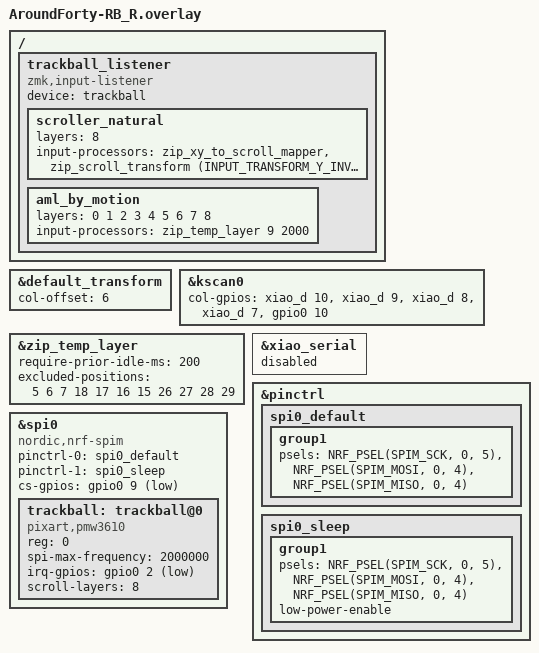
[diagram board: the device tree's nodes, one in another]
/* AroundForty-RB_R.overlay（Input Processor: AML + スクロールY反転 + excluded-positions + 2秒タイムアウト） */

#include "AroundForty-RB.dtsi"

/* Input Processor 利用 */
#include <input/processors.dtsi>
#include <dt-bindings/zmk/input_transform.h>

&default_transform {
    col-offset = <6>;
};

&kscan0 {
        col-gpios
            = <&xiao_d 10 GPIO_ACTIVE_HIGH>
            , <&xiao_d 9 GPIO_ACTIVE_HIGH>
            , <&xiao_d 8 GPIO_ACTIVE_HIGH>
            , <&xiao_d 7 GPIO_ACTIVE_HIGH>
            , <&gpio0 10 GPIO_ACTIVE_HIGH>
            ;
};

/* ▼ AML の“解除ルール”と“誤爆防止” */
&zip_temp_layer {
    /* 直前200ms以内にキー入力があれば AML を起動しない（誤爆防止） */
    require-prior-idle-ms = <200>;

    /* マウスキーの position → 押しても解除しない（指定以外は押したら即解除） */
    excluded-positions = <
        5 6 7
        18 17 16 15
        26 27 28 29
    >;
};

&xiao_serial { status = "disabled"; };

 /{
    /* トラックボール・リスナー */
    trackball_listener {
        compatible = "zmk,input-listener";
        device = <&trackball>;

        /* スクロール用レイヤのみで“縦スクロール反転”（ナチュラル想定） */
        scroller_natural {
            layers = <8>; /* ← Scloll_Layer のレイヤ番号に合わせる */
            input-processors =
                <&zip_xy_to_scroll_mapper>,
                <&zip_scroll_transform (INPUT_TRANSFORM_Y_INVERT)>;
        };

        /* AML：トラックボールを動かしたら MOUSE レイヤを 2秒だけ自動ON
           ※ layers が必須なので、デフォルト系レイヤ（0〜8）で発火させる */
        aml_by_motion {
            layers = <0 1 2 3 4 5 6 7 8>;
            input-processors = <&zip_temp_layer 9 2000>;
        };
    };
};

&pinctrl {
    spi0_default: spi0_default {
        group1 {
            psels = <NRF_PSEL(SPIM_SCK, 0, 5)>,
                <NRF_PSEL(SPIM_MOSI, 0, 4)>,
                <NRF_PSEL(SPIM_MISO, 0, 4)>;
        };
    };

    spi0_sleep: spi0_sleep {
        group1 {
            psels = <NRF_PSEL(SPIM_SCK, 0, 5)>,
                <NRF_PSEL(SPIM_MOSI, 0, 4)>,
                <NRF_PSEL(SPIM_MISO, 0, 4)>;
            low-power-enable;
        };
    };
};

&spi0 {
    status = "okay";
    compatible = "nordic,nrf-spim";
    pinctrl-0 = <&spi0_default>;
    pinctrl-1 = <&spi0_sleep>;
    pinctrl-names = "default", "sleep";
    cs-gpios = <&gpio0 9 GPIO_ACTIVE_LOW>;

    trackball: trackball@0 {
        status = "okay";
        compatible = "pixart,pmw3610";
        reg = <0>;
        spi-max-frequency = <2000000>;
        irq-gpios = <&gpio0 2 (GPIO_ACTIVE_LOW | GPIO_PULL_UP)>;

        /* pmw3610-driver のハードAMLは使わない（Input Processor を使用） */
        //automouse-layer = <6>;

        /* スクロール有効レイヤ（Scloll_Layer）番号 */
        scroll-layers = <8>;
    };
};
